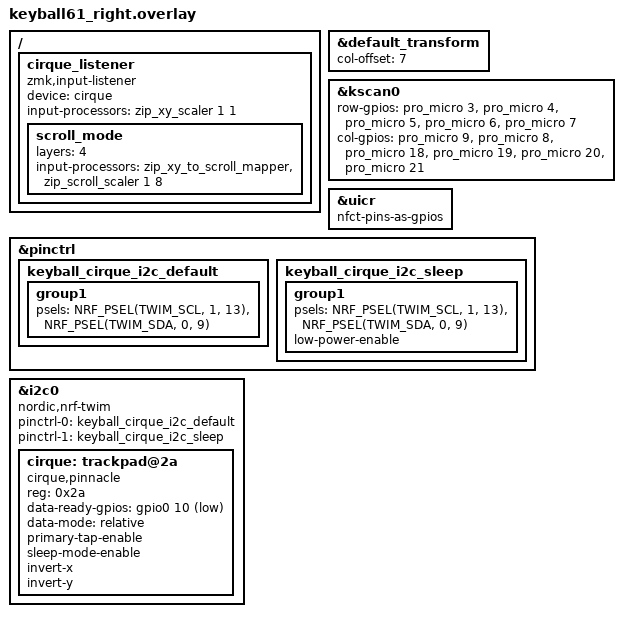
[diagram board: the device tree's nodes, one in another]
/*
 * Keyball61 right half + Cirque TM040040 / Rev M2 adapter.
 * SPDX-License-Identifier: MIT
 *
 * Frozen Rev M2 wiring:
 *   SCL -> P1.13 (Pro Micro D15 / Keyball J2-1)
 *   SDA -> P0.09 (Pro Micro D10 / Keyball J2-2)
 *   DR  -> P0.10 (Pro Micro D16 / Keyball J2-6)
 *   I2C address 0x2A
 *
 * Physical mounting: Cirque connector is at the LEFT (9 o'clock) side of
 * the installed pad, a 180-degree rotation from the datasheet orientation.
 * Therefore X and Y are BOTH inverted; there is NO XY swap.
 */

#include "keyball61.dtsi"
#include <zephyr/dt-bindings/gpio/gpio.h>
#include <zephyr/dt-bindings/pinctrl/nrf-pinctrl.h>
#include <input/processors.dtsi>

&default_transform {
    col-offset = <7>;
};

&kscan0 {
    row-gpios =
        <&pro_micro 3 (GPIO_ACTIVE_HIGH | GPIO_PULL_DOWN)>,
        <&pro_micro 4 (GPIO_ACTIVE_HIGH | GPIO_PULL_DOWN)>,
        <&pro_micro 5 (GPIO_ACTIVE_HIGH | GPIO_PULL_DOWN)>,
        <&pro_micro 6 (GPIO_ACTIVE_HIGH | GPIO_PULL_DOWN)>,
        <&pro_micro 7 (GPIO_ACTIVE_HIGH | GPIO_PULL_DOWN)>;

    col-gpios =
        <&pro_micro 9 GPIO_ACTIVE_HIGH>,
        <&pro_micro 8 GPIO_ACTIVE_HIGH>,
        <&pro_micro 18 GPIO_ACTIVE_HIGH>,
        <&pro_micro 19 GPIO_ACTIVE_HIGH>,
        <&pro_micro 20 GPIO_ACTIVE_HIGH>,
        <&pro_micro 21 GPIO_ACTIVE_HIGH>;
};

/* P0.09 and P0.10 are NFC-capable pins on nRF52840. */
&uicr {
    nfct-pins-as-gpios;
};

&pinctrl {
    keyball_cirque_i2c_default: keyball_cirque_i2c_default {
        group1 {
            psels = <NRF_PSEL(TWIM_SCL, 1, 13)>,
                    <NRF_PSEL(TWIM_SDA, 0, 9)>;
        };
    };

    keyball_cirque_i2c_sleep: keyball_cirque_i2c_sleep {
        group1 {
            psels = <NRF_PSEL(TWIM_SCL, 1, 13)>,
                    <NRF_PSEL(TWIM_SDA, 0, 9)>;
            low-power-enable;
        };
    };
};

&i2c0 {
    compatible = "nordic,nrf-twim";
    status = "okay";
    pinctrl-0 = <&keyball_cirque_i2c_default>;
    pinctrl-1 = <&keyball_cirque_i2c_sleep>;
    pinctrl-names = "default", "sleep";

    cirque: trackpad@2a {
        compatible = "cirque,pinnacle";
        reg = <0x2a>;
        status = "okay";

        /* Direct HW_DR: the current Zephyr binding intentionally specifies
         * ACTIVE_LOW even though the physical HW_DR signal asserts high.
         */
        data-ready-gpios = <&gpio0 10 GPIO_ACTIVE_LOW>;

        data-mode = "relative";
        primary-tap-enable;
        sleep-mode-enable;

        /* 180-degree physical rotation. */
        invert-x;
        invert-y;
    };
};

/ {
    cirque_listener: cirque_listener {
        compatible = "zmk,input-listener";
        device = <&cirque>;

        /* Start at 1:1. Tune after first hardware test if desired. */
        input-processors = <&zip_xy_scaler 1 1>;

        /* Layer 4 is the persistent SCROLL layer in keyball61.keymap.
         * When active, the entire pad becomes H/V scrolling. 1/8 keeps the
         * raw Cirque deltas from producing overly fast wheel motion.
         */
        scroll_mode {
            layers = <4>;
            input-processors = <
                &zip_xy_to_scroll_mapper
                &zip_scroll_scaler 1 8
            >;
        };
    };
};
